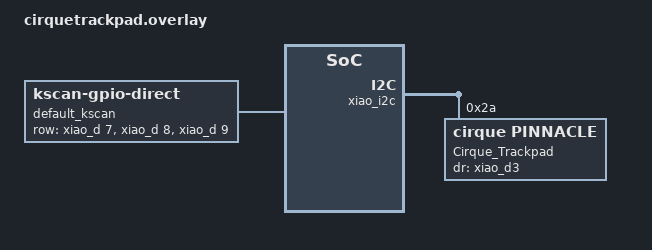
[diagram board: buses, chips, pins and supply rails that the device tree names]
// cirquetrackpad.overlay

/ {
    chosen {
        zmk,kscan = &default_kscan;
    };

    default_kscan: kscan {
        compatible = "zmk,kscan-gpio-direct";
        label = "default_kscan";

        row-gpios
            = <&xiao_d 7 (GPIO_ACTIVE_HIGH | GPIO_PULL_DOWN)> // Row A from the schematic file
            , <&xiao_d 8 (GPIO_ACTIVE_HIGH | GPIO_PULL_DOWN)> // Row B from the schematic file
            , <&xiao_d 9 (GPIO_ACTIVE_HIGH | GPIO_PULL_DOWN)> // Row C from the schematic file
            ;

    };
};

&xiao_i2c {
    status = "okay";
    trackpad@2a {
	    compatible = "cirque,pinnacle";
	    reg = <0x2a>;
	    label = "Cirque_Trackpad";
        dr-gpios = <&xiao_d3 GPIO_ACTIVE_HIGH>;
	    rotate-90;
	    //sleep;
	    //no-taps;
    };
};
